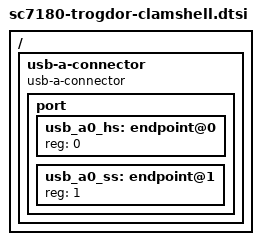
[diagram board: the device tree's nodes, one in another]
// SPDX-License-Identifier: (GPL-2.0+ OR MIT)
/*
 * Google Trogdor dts fragment for clamshells
 *
 * Copyright 2024 Google LLC.
 */

/* This file must be included after sc7180-trogdor.dtsi to modify cros_ec */
#include <arm/cros-ec-keyboard.dtsi>

/ {
	usb-a-connector {
		compatible = "usb-a-connector";

		port {
			#address-cells = <1>;
			#size-cells = <0>;

			usb_a0_hs: endpoint@0 {
				reg = <0>;
				/* Endpoint filled in by board */
			};

			usb_a0_ss: endpoint@1 {
				reg = <1>;
				/* Endpoint filled in by board */
			};
		};
	};
};
